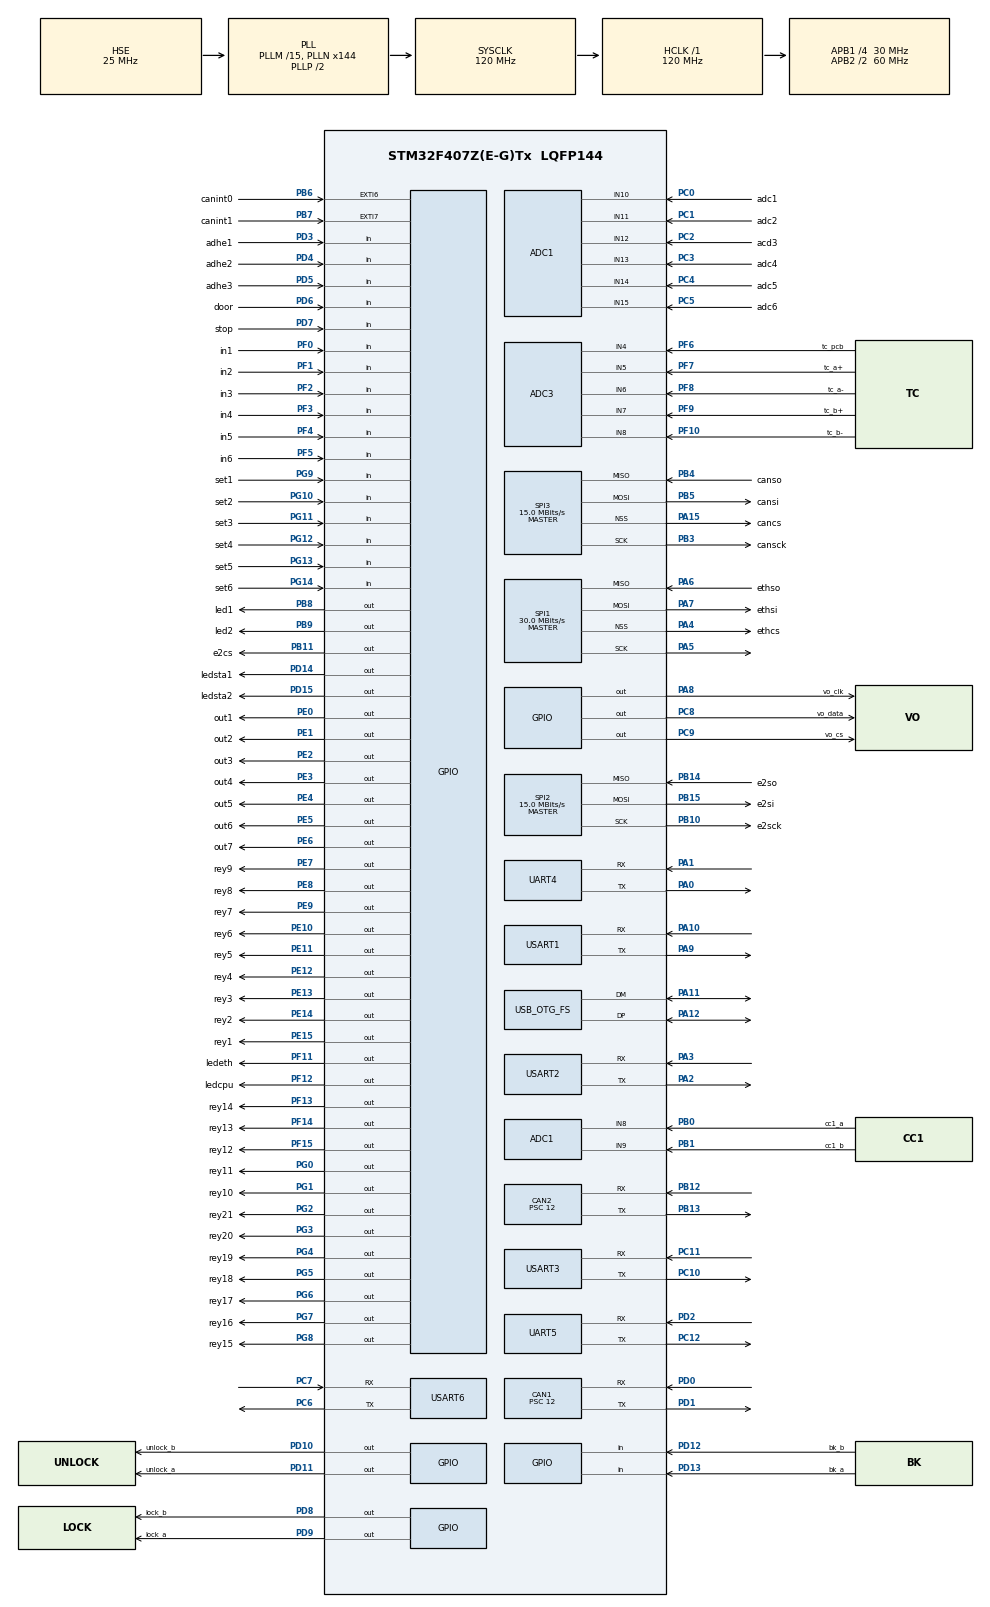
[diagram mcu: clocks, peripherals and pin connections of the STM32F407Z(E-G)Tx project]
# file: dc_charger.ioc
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ADC1.Channel-0\#ChannelRegularConversion=ADC_CHANNEL_8
ADC1.Channel-1\#ChannelRegularConversion=ADC_CHANNEL_9
ADC1.Channel-2\#ChannelRegularConversion=ADC_CHANNEL_10
ADC1.Channel-3\#ChannelRegularConversion=ADC_CHANNEL_11
ADC1.Channel-4\#ChannelRegularConversion=ADC_CHANNEL_12
ADC1.Channel-5\#ChannelRegularConversion=ADC_CHANNEL_13
ADC1.Channel-6\#ChannelRegularConversion=ADC_CHANNEL_14
ADC1.Channel-7\#ChannelRegularConversion=ADC_CHANNEL_15
ADC1.ContinuousConvMode=ENABLE
ADC1.DMAContinuousRequests=ENABLE
ADC1.NbrOfConversion=8
ADC1.NbrOfConversionFlag=1
ADC1.Rank-0\#ChannelRegularConversion=1
ADC1.Rank-1\#ChannelRegularConversion=2
ADC1.Rank-2\#ChannelRegularConversion=3
ADC1.Rank-3\#ChannelRegularConversion=4
ADC1.Rank-4\#ChannelRegularConversion=5
ADC1.Rank-5\#ChannelRegularConversion=6
ADC1.Rank-6\#ChannelRegularConversion=7
ADC1.Rank-7\#ChannelRegularConversion=8
ADC1.SamplingTime-0\#ChannelRegularConversion=ADC_SAMPLETIME_3CYCLES
ADC1.SamplingTime-1\#ChannelRegularConversion=ADC_SAMPLETIME_3CYCLES
ADC1.SamplingTime-2\#ChannelRegularConversion=ADC_SAMPLETIME_3CYCLES
ADC1.SamplingTime-3\#ChannelRegularConversion=ADC_SAMPLETIME_3CYCLES
ADC1.SamplingTime-4\#ChannelRegularConversion=ADC_SAMPLETIME_3CYCLES
ADC1.SamplingTime-5\#ChannelRegularConversion=ADC_SAMPLETIME_3CYCLES
ADC1.SamplingTime-6\#ChannelRegularConversion=ADC_SAMPLETIME_3CYCLES
ADC1.SamplingTime-7\#ChannelRegularConversion=ADC_SAMPLETIME_3CYCLES
ADC1.ScanConvMode=ENABLE
ADC1.master=1
ADC3.Channel-0\#ChannelRegularConversion=ADC_CHANNEL_4
ADC3.Channel-1\#ChannelRegularConversion=ADC_CHANNEL_5
ADC3.Channel-2\#ChannelRegularConversion=ADC_CHANNEL_6
ADC3.Channel-3\#ChannelRegularConversion=ADC_CHANNEL_7
ADC3.Channel-4\#ChannelRegularConversion=ADC_CHANNEL_8
ADC3.DMAContinuousRequests=ENABLE
ADC3.NbrOfConversion=5
ADC3.NbrOfConversionFlag=1
ADC3.Rank-0\#ChannelRegularConversion=1
ADC3.Rank-1\#ChannelRegularConversion=2
ADC3.Rank-2\#ChannelRegularConversion=3
ADC3.Rank-3\#ChannelRegularConversion=4
ADC3.Rank-4\#ChannelRegularConversion=5
ADC3.SamplingTime-0\#ChannelRegularConversion=ADC_SAMPLETIME_3CYCLES
ADC3.SamplingTime-1\#ChannelRegularConversion=ADC_SAMPLETIME_3CYCLES
ADC3.SamplingTime-2\#ChannelRegularConversion=ADC_SAMPLETIME_3CYCLES
ADC3.SamplingTime-3\#ChannelRegularConversion=ADC_SAMPLETIME_3CYCLES
ADC3.SamplingTime-4\#ChannelRegularConversion=ADC_SAMPLETIME_3CYCLES
ADC3.ScanConvMode=ENABLE
CAN1.ABOM=ENABLE
CAN1.BS1=CAN_BS1_3TQ
CAN1.BS2=CAN_BS2_6TQ
CAN1.CalculateBaudRate=250000
CAN1.CalculateTimeBit=4000
CAN1.CalculateTimeQuantum=400.0
CAN1.NART=ENABLE
CAN1.Prescaler=12
CAN2.ABOM=ENABLE
CAN2.BS1=CAN_BS1_3TQ
CAN2.BS2=CAN_BS2_6TQ
CAN2.CalculateBaudRate=250000
CAN2.CalculateTimeBit=4000
CAN2.CalculateTimeQuantum=400.0
CAN2.NART=ENABLE
CAN2.Prescaler=12
Dma.ADC1.0.Direction=DMA_PERIPH_TO_MEMORY
Dma.ADC1.0.FIFOMode=DMA_FIFOMODE_DISABLE
Dma.ADC1.0.Instance=DMA2_Stream4
Dma.ADC1.0.MemDataAlignment=DMA_MDATAALIGN_HALFWORD
Dma.ADC1.0.MemInc=DMA_MINC_ENABLE
Dma.ADC1.0.Mode=DMA_CIRCULAR
Dma.ADC1.0.PeriphDataAlignment=DMA_PDATAALIGN_HALFWORD
Dma.ADC1.0.PeriphInc=DMA_PINC_DISABLE
Dma.ADC1.0.Priority=DMA_PRIORITY_LOW
Dma.ADC3.1.Direction=DMA_PERIPH_TO_MEMORY
Dma.ADC3.1.FIFOMode=DMA_FIFOMODE_DISABLE
Dma.ADC3.1.Instance=DMA2_Stream0
Dma.ADC3.1.MemDataAlignment=DMA_MDATAALIGN_HALFWORD
Dma.ADC3.1.MemInc=DMA_MINC_ENABLE
Dma.ADC3.1.Mode=DMA_CIRCULAR
Dma.ADC3.1.PeriphDataAlignment=DMA_PDATAALIGN_HALFWORD
Dma.ADC3.1.PeriphInc=DMA_PINC_DISABLE
Dma.ADC3.1.Priority=DMA_PRIORITY_LOW
Dma.Request0=ADC1
Dma.Request1=ADC3
Dma.Request10=USART3_RX
Dma.Request11=USART3_TX
Dma.Request12=USART6_RX
Dma.Request13=USART6_TX
Dma.Request2=UART4_RX
Dma.Request3=UART4_TX
Dma.Request4=UART5_RX
Dma.Request5=UART5_TX
Dma.Request6=USART1_RX
Dma.Request7=USART1_TX
Dma.Request8=USART2_RX
Dma.Request9=USART2_TX
Dma.UART4_RX.2.Direction=DMA_PERIPH_TO_MEMORY
Dma.UART4_RX.2.FIFOMode=DMA_FIFOMODE_DISABLE
Dma.UART4_RX.2.Instance=DMA1_Stream2
Dma.UART4_RX.2.MemDataAlignment=DMA_MDATAALIGN_BYTE
Dma.UART4_RX.2.MemInc=DMA_MINC_ENABLE
Dma.UART4_RX.2.Mode=DMA_NORMAL
Dma.UART4_RX.2.PeriphDataAlignment=DMA_PDATAALIGN_BYTE
Dma.UART4_RX.2.PeriphInc=DMA_PINC_DISABLE
Dma.UART4_RX.2.Priority=DMA_PRIORITY_LOW
Dma.UART4_TX.3.Direction=DMA_MEMORY_TO_PERIPH
Dma.UART4_TX.3.FIFOMode=DMA_FIFOMODE_DISABLE
Dma.UART4_TX.3.Instance=DMA1_Stream4
Dma.UART4_TX.3.MemDataAlignment=DMA_MDATAALIGN_BYTE
Dma.UART4_TX.3.MemInc=DMA_MINC_ENABLE
Dma.UART4_TX.3.Mode=DMA_NORMAL
Dma.UART4_TX.3.PeriphDataAlignment=DMA_PDATAALIGN_BYTE
Dma.UART4_TX.3.PeriphInc=DMA_PINC_DISABLE
Dma.UART4_TX.3.Priority=DMA_PRIORITY_LOW
Dma.UART5_RX.4.Direction=DMA_PERIPH_TO_MEMORY
Dma.UART5_RX.4.FIFOMode=DMA_FIFOMODE_DISABLE
Dma.UART5_RX.4.Instance=DMA1_Stream0
Dma.UART5_RX.4.MemDataAlignment=DMA_MDATAALIGN_BYTE
Dma.UART5_RX.4.MemInc=DMA_MINC_ENABLE
Dma.UART5_RX.4.Mode=DMA_NORMAL
Dma.UART5_RX.4.PeriphDataAlignment=DMA_PDATAALIGN_BYTE
Dma.UART5_RX.4.PeriphInc=DMA_PINC_DISABLE
Dma.UART5_RX.4.Priority=DMA_PRIORITY_LOW
Dma.UART5_TX.5.Direction=DMA_MEMORY_TO_PERIPH
Dma.UART5_TX.5.FIFOMode=DMA_FIFOMODE_DISABLE
Dma.UART5_TX.5.Instance=DMA1_Stream7
Dma.UART5_TX.5.MemDataAlignment=DMA_MDATAALIGN_BYTE
Dma.UART5_TX.5.MemInc=DMA_MINC_ENABLE
Dma.UART5_TX.5.Mode=DMA_NORMAL
Dma.UART5_TX.5.PeriphDataAlignment=DMA_PDATAALIGN_BYTE
Dma.UART5_TX.5.PeriphInc=DMA_PINC_DISABLE
Dma.UART5_TX.5.Priority=DMA_PRIORITY_LOW
Dma.USART1_RX.6.Direction=DMA_PERIPH_TO_MEMORY
Dma.USART1_RX.6.FIFOMode=DMA_FIFOMODE_DISABLE
Dma.USART1_RX.6.Instance=DMA2_Stream2
Dma.USART1_RX.6.MemDataAlignment=DMA_MDATAALIGN_BYTE
Dma.USART1_RX.6.MemInc=DMA_MINC_ENABLE
Dma.USART1_RX.6.Mode=DMA_NORMAL
Dma.USART1_RX.6.PeriphDataAlignment=DMA_PDATAALIGN_BYTE
Dma.USART1_RX.6.PeriphInc=DMA_PINC_DISABLE
Dma.USART1_RX.6.Priority=DMA_PRIORITY_LOW
Dma.USART1_TX.7.Direction=DMA_MEMORY_TO_PERIPH
Dma.USART1_TX.7.FIFOMode=DMA_FIFOMODE_DISABLE
Dma.USART1_TX.7.Instance=DMA2_Stream7
Dma.USART1_TX.7.MemDataAlignment=DMA_MDATAALIGN_BYTE
Dma.USART1_TX.7.MemInc=DMA_MINC_ENABLE
Dma.USART1_TX.7.Mode=DMA_NORMAL
Dma.USART1_TX.7.PeriphDataAlignment=DMA_PDATAALIGN_BYTE
Dma.USART1_TX.7.PeriphInc=DMA_PINC_DISABLE
Dma.USART1_TX.7.Priority=DMA_PRIORITY_LOW
Dma.USART2_RX.8.Direction=DMA_PERIPH_TO_MEMORY
Dma.USART2_RX.8.FIFOMode=DMA_FIFOMODE_DISABLE
Dma.USART2_RX.8.Instance=DMA1_Stream5
Dma.USART2_RX.8.MemDataAlignment=DMA_MDATAALIGN_BYTE
Dma.USART2_RX.8.MemInc=DMA_MINC_ENABLE
Dma.USART2_RX.8.Mode=DMA_NORMAL
Dma.USART2_RX.8.PeriphDataAlignment=DMA_PDATAALIGN_BYTE
Dma.USART2_RX.8.PeriphInc=DMA_PINC_DISABLE
Dma.USART2_RX.8.Priority=DMA_PRIORITY_LOW
Dma.USART2_TX.9.Direction=DMA_MEMORY_TO_PERIPH
Dma.USART2_TX.9.FIFOMode=DMA_FIFOMODE_DISABLE
Dma.USART2_TX.9.Instance=DMA1_Stream6
Dma.USART2_TX.9.MemDataAlignment=DMA_MDATAALIGN_BYTE
Dma.USART2_TX.9.MemInc=DMA_MINC_ENABLE
Dma.USART2_TX.9.Mode=DMA_NORMAL
Dma.USART2_TX.9.PeriphDataAlignment=DMA_PDATAALIGN_BYTE
Dma.USART2_TX.9.PeriphInc=DMA_PINC_DISABLE
Dma.USART2_TX.9.Priority=DMA_PRIORITY_LOW
Dma.USART3_RX.10.Direction=DMA_PERIPH_TO_MEMORY
Dma.USART3_RX.10.FIFOMode=DMA_FIFOMODE_DISABLE
Dma.USART3_RX.10.Instance=DMA1_Stream1
Dma.USART3_RX.10.MemDataAlignment=DMA_MDATAALIGN_BYTE
Dma.USART3_RX.10.MemInc=DMA_MINC_ENABLE
Dma.USART3_RX.10.Mode=DMA_NORMAL
Dma.USART3_RX.10.PeriphDataAlignment=DMA_PDATAALIGN_BYTE
Dma.USART3_RX.10.PeriphInc=DMA_PINC_DISABLE
Dma.USART3_RX.10.Priority=DMA_PRIORITY_LOW
Dma.USART3_TX.11.Direction=DMA_MEMORY_TO_PERIPH
Dma.USART3_TX.11.FIFOMode=DMA_FIFOMODE_DISABLE
Dma.USART3_TX.11.Instance=DMA1_Stream3
Dma.USART3_TX.11.MemDataAlignment=DMA_MDATAALIGN_BYTE
Dma.USART3_TX.11.MemInc=DMA_MINC_ENABLE
Dma.USART3_TX.11.Mode=DMA_NORMAL
Dma.USART3_TX.11.PeriphDataAlignment=DMA_PDATAALIGN_BYTE
Dma.USART3_TX.11.PeriphInc=DMA_PINC_DISABLE
Dma.USART3_TX.11.Priority=DMA_PRIORITY_LOW
Dma.USART6_RX.12.Direction=DMA_PERIPH_TO_MEMORY
Dma.USART6_RX.12.FIFOMode=DMA_FIFOMODE_DISABLE
Dma.USART6_RX.12.Instance=DMA2_Stream1
Dma.USART6_RX.12.MemDataAlignment=DMA_MDATAALIGN_BYTE
Dma.USART6_RX.12.MemInc=DMA_MINC_ENABLE
Dma.USART6_RX.12.Mode=DMA_NORMAL
Dma.USART6_RX.12.PeriphDataAlignment=DMA_PDATAALIGN_BYTE
Dma.USART6_RX.12.PeriphInc=DMA_PINC_DISABLE
Dma.USART6_RX.12.Priority=DMA_PRIORITY_LOW
Dma.USART6_TX.13.Direction=DMA_MEMORY_TO_PERIPH
Dma.USART6_TX.13.FIFOMode=DMA_FIFOMODE_DISABLE
Dma.USART6_TX.13.Instance=DMA2_Stream6
Dma.USART6_TX.13.MemDataAlignment=DMA_MDATAALIGN_BYTE
Dma.USART6_TX.13.MemInc=DMA_MINC_ENABLE
Dma.USART6_TX.13.Mode=DMA_NORMAL
Dma.USART6_TX.13.PeriphDataAlignment=DMA_PDATAALIGN_BYTE
Dma.USART6_TX.13.PeriphInc=DMA_PINC_DISABLE
Dma.USART6_TX.13.Priority=DMA_PRIORITY_LOW
FATFS._FS_LOCK=8
FATFS._FS_RPATH=2
FREERTOS.INCLUDE_uxTaskGetStackHighWaterMark=1
FREERTOS.Tasks01=defaultTask,0,128,StartDefaultTask,Default,NULL,Dynamic,NULL,NULL
FREERTOS.configCHECK_FOR_STACK_OVERFLOW=1
FREERTOS.configGENERATE_RUN_TIME_STATS=1
FREERTOS.configTOTAL_HEAP_SIZE=65536
FREERTOS.configUSE_COUNTING_SEMAPHORES=1
FREERTOS.configUSE_IDLE_HOOK=1
FREERTOS.configUSE_STATS_FORMATTING_FUNCTIONS=1
FREERTOS.configUSE_TICK_HOOK=1
IWDG.Prescaler=IWDG_PRESCALER_32
MBEDTLS.MBEDTLS_DEBUG_C=1
MBEDTLS.MBEDTLS_ERROR_C=1
MBEDTLS.MBEDTLS_KEY_EXCHANGE_ECDHE_RSA_ENABLED=1
MBEDTLS.MBEDTLS_MPI_MAX_SIZE=256
MBEDTLS.MBEDTLS_PKCS1_V15=1
MBEDTLS.MBEDTLS_PLATFORM_MEMORY=1
MBEDTLS.MBEDTLS_PLATFORM_PRINTF_MACRO_ENABLE=0
MBEDTLS.MBEDTLS_RSA_C=1
MBEDTLS.MBEDTLS_SSL_CIPHERSUITES=MBEDTLS_TLS_ECDHE_ECDSA_WITH_AES_256_GCM_SHA384,MBEDTLS_TLS_ECDHE_ECDSA_WITH_AES_128_GCM_SHA256,MBEDTLS_TLS_ECDHE_RSA_WITH_AES_128_GCM_SHA256
MBEDTLS.MBEDTLS_SSL_MAX_CONTENT_LEN=6144
MBEDTLS.MBEDTLS_SSL_MAX_CONTENT_LEN_ENABLE=1
Mcu.Family=STM32F4
Mcu.Name=STM32F407Z(E-G)Tx
Mcu.Package=LQFP144
NVIC.CAN1_RX0_IRQn=true\:5\:0\:false\:false\:true\:true\:true\:true
NVIC.CAN1_TX_IRQn=true\:5\:0\:false\:false\:true\:true\:true\:true
NVIC.CAN2_RX1_IRQn=true\:5\:0\:false\:false\:true\:true\:true\:true
NVIC.CAN2_TX_IRQn=true\:5\:0\:false\:false\:true\:true\:true\:true
NVIC.DMA1_Stream0_IRQn=true\:5\:0\:false\:false\:true\:true\:false\:true
NVIC.DMA1_Stream1_IRQn=true\:5\:0\:false\:false\:true\:true\:false\:true
NVIC.DMA1_Stream2_IRQn=true\:5\:0\:false\:false\:true\:true\:false\:true
NVIC.DMA1_Stream3_IRQn=true\:5\:0\:false\:false\:true\:true\:false\:true
NVIC.DMA1_Stream4_IRQn=true\:5\:0\:false\:false\:true\:true\:false\:true
NVIC.DMA1_Stream5_IRQn=true\:5\:0\:false\:false\:true\:true\:false\:true
NVIC.DMA1_Stream6_IRQn=true\:5\:0\:false\:false\:true\:true\:false\:true
NVIC.DMA1_Stream7_IRQn=true\:5\:0\:false\:false\:true\:true\:false\:true
NVIC.DMA2_Stream0_IRQn=true\:5\:0\:false\:false\:true\:true\:false\:true
NVIC.DMA2_Stream1_IRQn=true\:5\:0\:false\:false\:true\:true\:false\:true
NVIC.DMA2_Stream2_IRQn=true\:5\:0\:false\:false\:true\:true\:false\:true
NVIC.DMA2_Stream4_IRQn=true\:5\:0\:false\:false\:true\:false\:false\:true
NVIC.DMA2_Stream6_IRQn=true\:5\:0\:false\:false\:true\:true\:false\:true
NVIC.DMA2_Stream7_IRQn=true\:5\:0\:false\:false\:true\:true\:false\:true
NVIC.OTG_FS_IRQn=true\:5\:0\:false\:false\:true\:true\:false\:true
NVIC.PriorityGroup=NVIC_PRIORITYGROUP_4
NVIC.SPI1_IRQn=true\:5\:0\:false\:false\:true\:true\:true\:true
NVIC.SPI2_IRQn=true\:5\:0\:false\:false\:true\:true\:true\:true
NVIC.SPI3_IRQn=true\:5\:0\:false\:false\:true\:true\:true\:true
NVIC.TIM1_UP_TIM10_IRQn=true\:15\:0\:false\:false\:true\:false\:false\:true
NVIC.TimeBase=TIM1_UP_TIM10_IRQn
NVIC.TimeBaseIP=TIM1
NVIC.UART4_IRQn=true\:5\:0\:false\:false\:true\:true\:true\:true
NVIC.UART5_IRQn=true\:5\:0\:false\:false\:true\:true\:true\:true
NVIC.USART1_IRQn=true\:5\:0\:false\:false\:true\:true\:true\:true
NVIC.USART2_IRQn=true\:5\:0\:false\:false\:true\:true\:true\:true
NVIC.USART3_IRQn=true\:5\:0\:false\:false\:true\:true\:true\:true
NVIC.USART6_IRQn=true\:5\:0\:false\:false\:true\:true\:true\:true
PA0-WKUP.Mode=Asynchronous
PA0-WKUP.Signal=UART4_TX
PA1.Mode=Asynchronous
PA1.Signal=UART4_RX
PA10.Mode=Asynchronous
PA10.Signal=USART1_RX
PA11.Mode=Host_Only
PA11.Signal=USB_OTG_FS_DM
PA12.Mode=Host_Only
PA12.Signal=USB_OTG_FS_DP
PA13.Mode=Serial_Wire
PA13.Signal=SYS_JTMS-SWDIO
PA14.Mode=Serial_Wire
PA14.Signal=SYS_JTCK-SWCLK
PA15.GPIO_Label=cancs
PA15.Mode=NSS_Signal_Hard_Output
PA15.Signal=SPI3_NSS
PA2.Mode=Asynchronous
PA2.Signal=USART2_TX
PA3.Mode=Asynchronous
PA3.Signal=USART2_RX
PA4.GPIO_Label=ethcs
PA4.Mode=NSS_Signal_Hard_Output
PA4.Signal=SPI1_NSS
PA5.Mode=Full_Duplex_Master
PA5.Signal=SPI1_SCK
PA6.GPIO_Label=ethso
PA6.Mode=Full_Duplex_Master
PA6.Signal=SPI1_MISO
PA7.GPIO_Label=ethsi
PA7.Mode=Full_Duplex_Master
PA7.Signal=SPI1_MOSI
PA8.GPIO_Label=vo_clk
PA8.Signal=GPIO_Output
PA9.Mode=Asynchronous
PA9.Signal=USART1_TX
PB0.GPIO_Label=cc1_a
PB0.Signal=ADCx_IN8
PB1.GPIO_Label=cc1_b
PB1.Signal=ADCx_IN9
PB10.GPIO_Label=e2sck
PB10.Mode=Full_Duplex_Master
PB10.Signal=SPI2_SCK
PB11.GPIO_Label=e2cs
PB11.Signal=GPIO_Output
PB12.Mode=CAN_Activate
PB12.Signal=CAN2_RX
PB13.Mode=CAN_Activate
PB13.Signal=CAN2_TX
PB14.GPIO_Label=e2so
PB14.Mode=Full_Duplex_Master
PB14.Signal=SPI2_MISO
PB15.GPIO_Label=e2si
PB15.Mode=Full_Duplex_Master
PB15.Signal=SPI2_MOSI
PB3.GPIO_Label=cansck
PB3.Mode=Full_Duplex_Master
PB3.Signal=SPI3_SCK
PB4.GPIO_Label=canso
PB4.Mode=Full_Duplex_Master
PB4.Signal=SPI3_MISO
PB5.GPIO_Label=cansi
PB5.Mode=Full_Duplex_Master
PB5.Signal=SPI3_MOSI
PB6.GPIO_Label=canint0
PB6.Signal=GPXTI6
PB7.GPIO_Label=canint1
PB7.Signal=GPXTI7
PB8.GPIO_Label=led1
PB8.Signal=GPIO_Output
PB9.GPIO_Label=led2
PB9.Signal=GPIO_Output
PC0.GPIO_Label=adc1
PC0.Signal=ADCx_IN10
PC1.GPIO_Label=adc2
PC1.Signal=ADCx_IN11
PC10.Mode=Asynchronous
PC10.Signal=USART3_TX
PC11.Mode=Asynchronous
PC11.Signal=USART3_RX
PC12.Mode=Asynchronous
PC12.Signal=UART5_TX
PC13-ANTI_TAMP.Signal=RTC_AF1
PC14-OSC32_IN.Mode=LSE-External-Oscillator
PC14-OSC32_IN.Signal=RCC_OSC32_IN
PC15-OSC32_OUT.Mode=LSE-External-Oscillator
PC15-OSC32_OUT.Signal=RCC_OSC32_OUT
PC2.GPIO_Label=acd3
PC2.Signal=ADCx_IN12
PC3.GPIO_Label=adc4
PC3.Signal=ADCx_IN13
PC4.GPIO_Label=adc5
PC4.Signal=ADCx_IN14
PC5.GPIO_Label=adc6
PC5.Signal=ADCx_IN15
PC6.Mode=Asynchronous
PC6.Signal=USART6_TX
PC7.Mode=Asynchronous
PC7.Signal=USART6_RX
PC8.GPIO_Label=vo_data
PC8.Signal=GPIO_Output
PC9.GPIO_Label=vo_cs
PC9.Signal=GPIO_Output
PD0.Mode=CAN_Activate
PD0.Signal=CAN1_RX
PD1.Mode=CAN_Activate
PD1.Signal=CAN1_TX
PD10.GPIO_Label=unlock_b
PD10.Signal=GPIO_Output
PD11.GPIO_Label=unlock_a
PD11.Signal=GPIO_Output
PD12.GPIO_Label=bk_b
PD12.Signal=GPIO_Input
PD13.GPIO_Label=bk_a
PD13.Signal=GPIO_Input
PD14.GPIO_Label=ledsta1
PD14.Signal=GPIO_Output
PD15.GPIO_Label=ledsta2
PD15.Signal=GPIO_Output
PD2.Mode=Asynchronous
PD2.Signal=UART5_RX
PD3.GPIO_Label=adhe1
PD3.Signal=GPIO_Input
PD4.GPIO_Label=adhe2
PD4.Signal=GPIO_Input
PD5.GPIO_Label=adhe3
PD5.Signal=GPIO_Input
PD6.GPIO_Label=door
PD6.Signal=GPIO_Input
PD7.GPIO_Label=stop
PD7.Signal=GPIO_Input
PD8.GPIO_Label=lock_b
PD8.Signal=GPIO_Output
PD9.GPIO_Label=lock_a
PD9.Signal=GPIO_Output
PE0.GPIO_Label=out1
PE0.Signal=GPIO_Output
PE1.GPIO_Label=out2
PE1.Signal=GPIO_Output
PE10.GPIO_Label=rey6
PE10.Signal=GPIO_Output
PE11.GPIO_Label=rey5
PE11.Signal=GPIO_Output
PE12.GPIO_Label=rey4
PE12.Signal=GPIO_Output
PE13.GPIO_Label=rey3
PE13.Signal=GPIO_Output
PE14.GPIO_Label=rey2
PE14.Signal=GPIO_Output
PE15.GPIO_Label=rey1
PE15.Signal=GPIO_Output
PE2.GPIO_Label=out3
PE2.Signal=GPIO_Output
PE3.GPIO_Label=out4
PE3.Signal=GPIO_Output
PE4.GPIO_Label=out5
PE4.Signal=GPIO_Output
PE5.GPIO_Label=out6
PE5.Signal=GPIO_Output
PE6.GPIO_Label=out7
PE6.Signal=GPIO_Output
PE7.GPIO_Label=rey9
PE7.Signal=GPIO_Output
PE8.GPIO_Label=rey8
PE8.Signal=GPIO_Output
PE9.GPIO_Label=rey7
PE9.Signal=GPIO_Output
PF0.GPIO_Label=in1
PF0.Signal=GPIO_Input
PF1.GPIO_Label=in2
PF1.Signal=GPIO_Input
PF10.GPIO_Label=tc_b-
PF10.Mode=IN8
PF10.Signal=ADC3_IN8
PF11.GPIO_Label=ledeth
PF11.Signal=GPIO_Output
PF12.GPIO_Label=ledcpu
PF12.Signal=GPIO_Output
PF13.GPIO_Label=rey14
PF13.Signal=GPIO_Output
PF14.GPIO_Label=rey13
PF14.Signal=GPIO_Output
PF15.GPIO_Label=rey12
PF15.Signal=GPIO_Output
PF2.GPIO_Label=in3
PF2.Signal=GPIO_Input
PF3.GPIO_Label=in4
PF3.Signal=GPIO_Input
PF4.GPIO_Label=in5
PF4.Signal=GPIO_Input
PF5.GPIO_Label=in6
PF5.Signal=GPIO_Input
PF6.GPIO_Label=tc_pcb
PF6.Mode=IN4
PF6.Signal=ADC3_IN4
PF7.GPIO_Label=tc_a+
PF7.Mode=IN5
PF7.Signal=ADC3_IN5
PF8.GPIO_Label=tc_a-
PF8.Mode=IN6
PF8.Signal=ADC3_IN6
PF9.GPIO_Label=tc_b+
PF9.Mode=IN7
PF9.Signal=ADC3_IN7
PG0.GPIO_Label=rey11
PG0.Signal=GPIO_Output
PG1.GPIO_Label=rey10
PG1.Signal=GPIO_Output
PG10.GPIO_Label=set2
PG10.Signal=GPIO_Input
PG11.GPIO_Label=set3
PG11.Signal=GPIO_Input
PG12.GPIO_Label=set4
PG12.Signal=GPIO_Input
PG13.GPIO_Label=set5
PG13.Signal=GPIO_Input
PG14.GPIO_Label=set6
PG14.Signal=GPIO_Input
PG2.GPIO_Label=rey21
PG2.Signal=GPIO_Output
PG3.GPIO_Label=rey20
PG3.Signal=GPIO_Output
PG4.GPIO_Label=rey19
PG4.Signal=GPIO_Output
PG5.GPIO_Label=rey18
PG5.Signal=GPIO_Output
PG6.GPIO_Label=rey17
PG6.Signal=GPIO_Output
PG7.GPIO_Label=rey16
PG7.Signal=GPIO_Output
PG8.GPIO_Label=rey15
PG8.Signal=GPIO_Output
PG9.GPIO_Label=set1
PG9.Signal=GPIO_Input
PH0-OSC_IN.Mode=HSE-External-Oscillator
PH0-OSC_IN.Signal=RCC_OSC_IN
PH1-OSC_OUT.Mode=HSE-External-Oscillator
PH1-OSC_OUT.Signal=RCC_OSC_OUT
ProjectManager.HeapSize=0x14000
ProjectManager.StackSize=0x400
ProjectManager.TargetToolchain=Makefile
RCC.48MHZClocksFreq_Value=48000000
RCC.AHBFreq_Value=120000000
RCC.APB1CLKDivider=RCC_HCLK_DIV4
RCC.APB1Freq_Value=30000000
RCC.APB1TimFreq_Value=60000000
RCC.APB2CLKDivider=RCC_HCLK_DIV2
RCC.APB2Freq_Value=60000000
RCC.APB2TimFreq_Value=120000000
RCC.CortexFreq_Value=120000000
RCC.HCLKFreq_Value=120000000
RCC.HSE_VALUE=25000000
RCC.HSI_VALUE=16000000
RCC.PLLM=20
RCC.PLLQ=5
RCC.RCC_RTC_Clock_Source=RCC_RTCCLKSOURCE_LSE
RCC.RCC_RTC_Clock_SourceVirtual=RCC_RTCCLKSOURCE_LSE
RCC.SYSCLKFreq_VALUE=120000000
RCC.SYSCLKSource=RCC_SYSCLKSOURCE_PLLCLK
RCC.VCOOutputFreq_Value=240000000
SH.ADCx_IN10.0=ADC1_IN10,IN10
SH.ADCx_IN11.0=ADC1_IN11,IN11
SH.ADCx_IN12.0=ADC1_IN12,IN12
SH.ADCx_IN13.0=ADC1_IN13,IN13
SH.ADCx_IN14.0=ADC1_IN14,IN14
SH.ADCx_IN15.0=ADC1_IN15,IN15
SH.ADCx_IN8.0=ADC1_IN8,IN8
SH.ADCx_IN9.0=ADC1_IN9,IN9
SPI1.CalculateBaudRate=30.0 MBits/s
SPI1.Direction=SPI_DIRECTION_2LINES
SPI1.Mode=SPI_MODE_MASTER
SPI1.VirtualNSS=VM_NSSHARD
SPI1.VirtualType=VM_MASTER
SPI2.CalculateBaudRate=15.0 MBits/s
SPI2.Direction=SPI_DIRECTION_2LINES
SPI2.Mode=SPI_MODE_MASTER
SPI2.VirtualType=VM_MASTER
SPI3.CalculateBaudRate=15.0 MBits/s
SPI3.Direction=SPI_DIRECTION_2LINES
SPI3.Mode=SPI_MODE_MASTER
SPI3.VirtualNSS=VM_NSSHARD
SPI3.VirtualType=VM_MASTER
UART4.VirtualMode=Asynchronous
UART5.VirtualMode=Asynchronous
USART1.VirtualMode=VM_ASYNC
USART2.VirtualMode=VM_ASYNC
USART3.VirtualMode=VM_ASYNC
USART6.VirtualMode=VM_ASYNC
USB_HOST.USBH_HandleTypeDef-MSC_FS=hUsbHostFS
USB_HOST.USBH_USE_OS-MSC_FS=0
USB_HOST.VirtualModeFS=Msc
USB_OTG_FS.VirtualMode=Host_Only
USB_OTG_FS.phy_itface=HCD_PHY_EMBEDDED
VP_FATFS_VS_USB.Mode=USB
VP_FREERTOS_VS_CMSIS_V1.Mode=CMSIS_V1
VP_IWDG_VS_IWDG.Mode=IWDG_Activate
VP_MBEDTLS_VS_MBEDTLS.Mode=Enabled
VP_RNG_VS_RNG.Mode=RNG_Activate
VP_RTC_VS_RTC_Activate.Mode=RTC_Enabled
VP_RTC_VS_RTC_Calendar.Mode=RTC_Calendar
VP_SYS_VS_tim1.Mode=TIM1
VP_USB_HOST_VS_USB_HOST_MSC_FS.Mode=MSC_FS
board=custom

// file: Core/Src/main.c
/* USER CODE BEGIN Header */
/**
  ******************************************************************************
  * @file           : main.c
  * @brief          : Main program body
  ******************************************************************************
  * @attention
  *
  * Copyright (c) 2022 STMicroelectronics.
  * All rights reserved.
  *
  * This software is licensed under terms that can be found in the LICENSE file
  * in the root directory of this software component.
  * If no LICENSE file comes with this software, it is provided AS-IS.
  *
  ******************************************************************************
  */
/* USER CODE END Header */
#include "main.h"
#include "cmsis_os.h"
#include "adc.h"
#include "can.h"
#include "dma.h"
#include "fatfs.h"
#include "iwdg.h"
#include "mbedtls.h"
#include "rng.h"
#include "rtc.h"
#include "spi.h"
#include "usart.h"
#include "usb_host.h"
#include "gpio.h"

/* USER CODE BEGIN Includes */

#include "iap.h"
#include "early_sys_callback.h"

/* USER CODE END Includes */

void SystemClock_Config(void);
void MX_FREERTOS_Init(void);

int main(void)
{
  /* USER CODE BEGIN 1 */

  try_to_start_app();

  /* USER CODE END 1 */

  /* MCU Configuration--------------------------------------------------------*/

  /* Reset of all peripherals, Initializes the Flash interface and the Systick. */
  HAL_Init();

  /* Configure the system clock */
  SystemClock_Config();

  /* USER CODE BEGIN SysInit */

  early_sys_callback();

  /* USER CODE END SysInit */

  /* Initialize all configured peripherals */
  MX_GPIO_Init();
  MX_ADC1_Init();
  MX_ADC3_Init();
  MX_CAN1_Init();
  MX_CAN2_Init();
  MX_RNG_Init();
  MX_SPI1_Init();
  MX_SPI2_Init();
  MX_SPI3_Init();
  MX_UART4_Init();
  MX_UART5_Init();
  MX_USART1_UART_Init();
  MX_USART2_UART_Init();
  MX_USART3_UART_Init();
  MX_USART6_UART_Init();
  MX_FATFS_Init();
  MX_MBEDTLS_Init();
  MX_DMA_Init();
  MX_RTC_Init();
  MX_IWDG_Init();

  /* Call init function for freertos objects (in freertos.c) */
  MX_FREERTOS_Init();
  /* Start scheduler */
  osKernelStart();

  /* We should never get here as control is now taken by the scheduler */
  /* Infinite loop */
  while (1)
  {

  }
}

void SystemClock_Config(void)
{
  RCC_OscInitTypeDef RCC_OscInitStruct = {0};
  RCC_ClkInitTypeDef RCC_ClkInitStruct = {0};

  /** Configure the main internal regulator output voltage
  */
  __HAL_RCC_PWR_CLK_ENABLE();
  __HAL_PWR_VOLTAGESCALING_CONFIG(PWR_REGULATOR_VOLTAGE_SCALE1);
  /** Initializes the RCC Oscillators according to the specified parameters
  * in the RCC_OscInitTypeDef structure.
  */
  RCC_OscInitStruct.OscillatorType = RCC_OSCILLATORTYPE_LSI|RCC_OSCILLATORTYPE_HSE
                              |RCC_OSCILLATORTYPE_LSE;
  RCC_OscInitStruct.HSEState = RCC_HSE_ON;
  RCC_OscInitStruct.LSEState = RCC_LSE_ON;
  RCC_OscInitStruct.LSIState = RCC_LSI_ON;
  RCC_OscInitStruct.PLL.PLLState = RCC_PLL_ON;
  RCC_OscInitStruct.PLL.PLLSource = RCC_PLLSOURCE_HSE;
  RCC_OscInitStruct.PLL.PLLM = 15;
  RCC_OscInitStruct.PLL.PLLN = 144;
  RCC_OscInitStruct.PLL.PLLP = RCC_PLLP_DIV2;
  RCC_OscInitStruct.PLL.PLLQ = 5;
  if (HAL_RCC_OscConfig(&RCC_OscInitStruct) != HAL_OK)
  {
    Error_Handler();
  }
  /** Initializes the CPU, AHB and APB buses clocks
  */
  RCC_ClkInitStruct.ClockType = RCC_CLOCKTYPE_HCLK|RCC_CLOCKTYPE_SYSCLK
                              |RCC_CLOCKTYPE_PCLK1|RCC_CLOCKTYPE_PCLK2;
  RCC_ClkInitStruct.SYSCLKSource = RCC_SYSCLKSOURCE_PLLCLK;
  RCC_ClkInitStruct.AHBCLKDivider = RCC_SYSCLK_DIV1;
  RCC_ClkInitStruct.APB1CLKDivider = RCC_HCLK_DIV4;
  RCC_ClkInitStruct.APB2CLKDivider = RCC_HCLK_DIV2;

  if (HAL_RCC_ClockConfig(&RCC_ClkInitStruct, FLASH_LATENCY_3) != HAL_OK)
  {
    Error_Handler();
  }
}

void HAL_TIM_PeriodElapsedCallback(TIM_HandleTypeDef *htim)
{
  if (htim->Instance == TIM1) {
    HAL_IncTick();
  }
}

void Error_Handler(void)
{
  __disable_irq();
  while (1)
  {
  }
}
